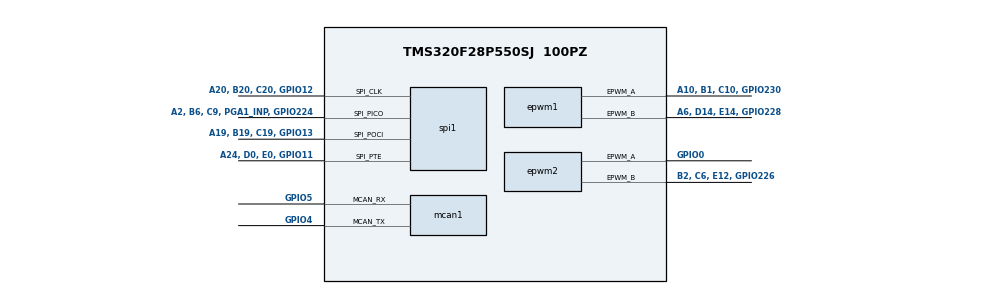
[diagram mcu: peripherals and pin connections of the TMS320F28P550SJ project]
/**
 * AI AGENTS: Do not edit this file directly. There is no validation or error feedback when
 * editing manually — mistakes will be silent until the file is loaded in SysConfig.
 * Use the SysConfig MCP server instead to make changes with immediate error reporting.
 *
 * These arguments were used when this file was generated. They will be automatically applied on subsequent loads
 * via the GUI or CLI. Run CLI with '--help' for additional information on how to override these arguments.
 * @cliArgs --device "F28P55x" --part "F28P55x_100PZ" --package "100PZ" --context "system" --product "C2000WARE@26.01.00.00"
 * @v2CliArgs --device "TMS320F28P550SJ" --package "100PZ" --variant "TMS320F28P550SJ9" --context "system" --product "C2000WARE@26.01.00.00"
 * @versions {"tool":"1.28.0+4696"}
 */

/**
 * Import the modules used in this configuration.
 */
const device_support = scripting.addModule("/driverlib/device_support.js");
const epwm           = scripting.addModule("/driverlib/epwm.js", {}, false);
const epwm1          = epwm.addInstance();
const epwm2          = epwm.addInstance();
const mcan           = scripting.addModule("/driverlib/mcan.js", {}, false);
const mcan1          = mcan.addInstance();
const spi            = scripting.addModule("/driverlib/spi.js", {}, false);
const spi1           = spi.addInstance();

/**
 * Write custom configuration values to the imported modules.
 */
const divider4       = system.clockTree["MCANACLKDIV"];
divider4.divideValue = 1;

epwm1.$name                  = "myEPWM1";
epwm1.epwm.$assign           = "EPWM2";
epwm1.epwm.epwm_aPin.$assign = "A10, B1, C10, GPIO230";
epwm1.epwm.epwm_bPin.$assign = "A6, D14, E14, GPIO228";

epwm2.$name                  = "myEPWM2";
epwm2.epwm.$assign           = "EPWM1";
epwm2.epwm.epwm_aPin.$assign = "GPIO0";
epwm2.epwm.epwm_bPin.$assign = "B2, C6, E12, GPIO226";

mcan1.loopbackMode             = false;
mcan1.enableInterrupt          = true;
mcan1.interruptLine            = ["MCAN_INTR_LINE_NUM_0"];
mcan1.registerInterruptLine0   = true;
mcan1.nomTimeSeg1              = 11;
mcan1.nomTimeSeg2              = 11;
mcan1.nomSynchJumpWidth        = 10;
mcan1.rxBufElemSize            = "0";
mcan1.txBufElemSize            = "0";
mcan1.rxFIFO0OpMode            = "1";
mcan1.rxFIFO1OpMode            = "1";
mcan1.lse                      = 0;
mcan1.stdFilts                 = 1;
mcan1.rrfs                     = true;
mcan1.rrfe                     = true;
mcan1.rxFIFO0size              = 3;
mcan1.rxFIFO0ElemSize          = "0";
mcan1.interruptFlags           = ["MCAN_IR_RF0N_MASK"];
mcan1.interruptLine0Flag       = ["MCAN_IR_RF0N_MASK"];
mcan1.$name                    = "myMCANA";
mcan1.tdcEnable                = true;
mcan1.additionalCoreConfig     = true;
mcan1.timeoutSelect            = "MCAN_TIMEOUT_SELECT_RX_FIFO0";
mcan1.anfe                     = "2";
mcan1.anfs                     = "2";
mcan1.stdFiltsUsed             = [0];
mcan1.txBufNum                 = 16;
mcan1.useCalcStartingAddress   = true;
mcan1.emulationEnable          = true;
mcan1.darEnable                = true;
mcan1.efbi                     = true;
mcan1.nomRatePrescalar         = 5;
mcan1.dataRatePrescalar        = 2;
mcan1.dataTimeSeg1             = 11;
mcan1.dataTimeSeg2             = 11;
mcan1.dataSynchJumpWidth       = 10;
mcan1.mcan.$assign             = "MCANA";
mcan1.mcan.mcan_rxPin.$assign  = "GPIO5";
mcan1.mcan.mcan_txPin.$assign  = "GPIO4";
mcan1.mcanInt0.enableInterrupt = true;
mcan1.stdFilt0.$name           = "stdFilt1";
mcan1.stdFilt0.sfid1           = 2;
mcan1.stdFilt0.sfid2           = 2;
mcan1.stdFilt0.sfec            = "MCAN_STDFILTEC_FIFO0";

spi1.$name                   = "mySPIB";
spi1.spi.$assign             = "SPIA";
spi1.spi.spi_picoPin.$assign = "A2, B6, C9, PGA1_INP, GPIO224";
spi1.spi.spi_pociPin.$assign = "A19, B19, C19, GPIO13";
spi1.spi.spi_clkPin.$assign  = "A20, B20, C20, GPIO12";
spi1.spi.spi_ptePin.$assign  = "A24, D0, E0, GPIO11";
spi1.picoQual.$name          = "myGPIOQUAL0";
spi1.pociQual.$name          = "myGPIOQUAL1";
spi1.clkQual.$name           = "myGPIOQUAL2";
spi1.pteQual.$name           = "myGPIOQUAL3";
